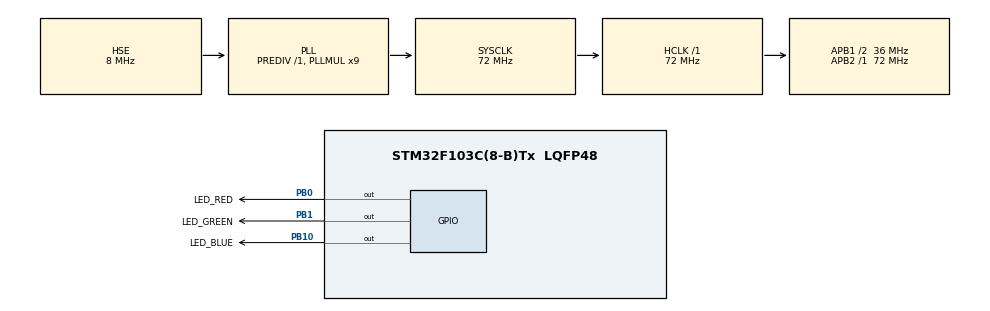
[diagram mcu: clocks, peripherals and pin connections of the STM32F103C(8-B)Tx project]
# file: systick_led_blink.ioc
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Mcu.Family=STM32F1
Mcu.Name=STM32F103C(8-B)Tx
Mcu.Package=LQFP48
NVIC.PriorityGroup=NVIC_PRIORITYGROUP_4
PA13.Mode=Serial_Wire
PA13.Signal=SYS_JTMS-SWDIO
PA14.Mode=Serial_Wire
PA14.Signal=SYS_JTCK-SWCLK
PB0.GPIO_Label=LED_RED
PB0.PinState=GPIO_PIN_SET
PB0.Signal=GPIO_Output
PB1.GPIO_Label=LED_GREEN
PB1.PinState=GPIO_PIN_SET
PB1.Signal=GPIO_Output
PB10.GPIO_Label=LED_BLUE
PB10.PinState=GPIO_PIN_SET
PB10.Signal=GPIO_Output
PD0-OSC_IN.Mode=HSE-External-Oscillator
PD0-OSC_IN.Signal=RCC_OSC_IN
PD1-OSC_OUT.Mode=HSE-External-Oscillator
PD1-OSC_OUT.Signal=RCC_OSC_OUT
ProjectManager.HeapSize=0x200
ProjectManager.StackSize=0x400
ProjectManager.TargetToolchain=CMake
RCC.AHBFreq_Value=72000000
RCC.APB1CLKDivider=RCC_HCLK_DIV2
RCC.APB1Freq_Value=36000000
RCC.APB1TimFreq_Value=72000000
RCC.APB2Freq_Value=72000000
RCC.APB2TimFreq_Value=72000000
RCC.HCLKFreq_Value=72000000
RCC.PLLMUL=RCC_PLL_MUL9
RCC.PLLSourceVirtual=RCC_PLLSOURCE_HSE
RCC.SYSCLKFreq_VALUE=72000000
RCC.SYSCLKSource=RCC_SYSCLKSOURCE_PLLCLK
RCC.USBFreq_Value=72000000
board=custom

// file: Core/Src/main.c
/* USER CODE BEGIN Header */
/**
  ******************************************************************************
  * @file           : main.c
  * @brief          : Main program body
  ******************************************************************************
  * @attention
  *
  * Copyright (c) 2025 STMicroelectronics.
  * All rights reserved.
  *
  * This software is licensed under terms that can be found in the LICENSE file
  * in the root directory of this software component.
  * If no LICENSE file comes with this software, it is provided AS-IS.
  *
  ******************************************************************************
  */
/* USER CODE END Header */
#include "main.h"
#include "gpio.h"
#include "stm32f103xb.h"
#include "stm32f1xx_hal_gpio.h"
#include "stm32f1xx_it.h"
#include <stdint.h>

/* USER CODE BEGIN PD */

// 定义LED引脚和端口
#define LEDR_PIN GPIO_PIN_0
#define LEDR_GPIO_PORT GPIOB
#define LEDG_PIN GPIO_PIN_1
#define LEDG_GPIO_PORT GPIOB
#define LEDB_PIN GPIO_PIN_10
#define LEDB_GPIO_PORT GPIOB

/* USER CODE END PD */

/* USER CODE BEGIN PV */

volatile uint32_t tick_count = 0; // 毫秒计数器
volatile uint8_t led_state = 0;  // LED状态变量, 0: 红, 1: 绿, 2: 蓝

/* USER CODE END PV */

void SystemClock_Config(void);
/* USER CODE BEGIN PFP */

void SysTick_Init(uint32_t ticks);
void SysTick_Handler(void);

/* USER CODE END PFP */

/* USER CODE BEGIN 0 */

/**
  * @brief  初始化SysTick定时器
  * @param  ticks: 定时器重载值
  * @retval None
  */
void SysTick_Init(uint32_t ticks) {
  // 关闭SysTick定时器
  SysTick->CTRL = 0;

  // 设置重载寄存器
  SysTick->LOAD = ticks - 1;

  // 设置中断优先级
  NVIC_SetPriority(SysTick_IRQn, 0x0);

  // 重置计数器
  SysTick->VAL = 0;

  // 启用SysTick定时器，选择系统时钟，并启用中断
  SysTick->CTRL = SysTick_CTRL_CLKSOURCE_Msk |
                 SysTick_CTRL_TICKINT_Msk |
                 SysTick_CTRL_ENABLE_Msk;
}

/**
  * @brief  SysTick中断服务程序
  * @param  None
  * @retval None
  */
void SysTick_Handler(void)
{
  /* USER CODE BEGIN SysTick_IRQn 0 */

  tick_count++;

  // 每1000ms切换一次LED状态
  if (tick_count % 1000 == 0) {
    // 关闭所有LED
    HAL_GPIO_WritePin(LEDR_GPIO_PORT, LEDR_PIN, GPIO_PIN_SET);
    HAL_GPIO_WritePin(LEDG_GPIO_PORT, LEDG_PIN, GPIO_PIN_SET);
    HAL_GPIO_WritePin(LEDB_GPIO_PORT, LEDB_PIN, GPIO_PIN_SET);

   // 根据当前状态点亮对应的LED
    switch (led_state) {
      case 0:
        HAL_GPIO_WritePin(LEDR_GPIO_PORT, LEDR_PIN, GPIO_PIN_RESET); // 点亮红色LED
        break;
      case 1:
        HAL_GPIO_WritePin(LEDG_GPIO_PORT, LEDG_PIN, GPIO_PIN_RESET); // 点亮绿色LED
        break;
      case 2:
        HAL_GPIO_WritePin(LEDB_GPIO_PORT, LEDB_PIN, GPIO_PIN_RESET); // 点亮蓝色LED
        break;
    }

    // 更新LED状态
    led_state = (led_state + 1) % 3; // 循环切换状态
  }

  /* USER CODE END SysTick_IRQn 0 */
  HAL_IncTick();
  /* USER CODE BEGIN SysTick_IRQn 1 */

  /* USER CODE END SysTick_IRQn 1 */
}

/* USER CODE END 0 */

int main(void)
{

  /* MCU Configuration--------------------------------------------------------*/

  /* Reset of all peripherals, Initializes the Flash interface and the Systick. */
  HAL_Init();

  /* Configure the system clock */
  SystemClock_Config();

  /* Initialize all configured peripherals */
  MX_GPIO_Init();
  /* USER CODE BEGIN 2 */

  // 初始化SysTick定时器，系统时钟为72MHz，每1ms中断一次
  SysTick_Init(72000);

  // 初始化时，关闭所有LED
  HAL_GPIO_WritePin(LEDR_GPIO_PORT, LEDR_PIN, GPIO_PIN_SET);
  HAL_GPIO_WritePin(LEDG_GPIO_PORT, LEDG_PIN, GPIO_PIN_SET);
  HAL_GPIO_WritePin(LEDB_GPIO_PORT, LEDB_PIN, GPIO_PIN_SET);

  /* USER CODE END 2 */

  /* Infinite loop */
  while (1)
  {

    /* USER CODE BEGIN 3 */

    // 主循环中不需要做任何事情，所有操作都在SysTick中断中处理
  }
  /* USER CODE END 3 */
}

void SystemClock_Config(void)
{
  RCC_OscInitTypeDef RCC_OscInitStruct = {0};
  RCC_ClkInitTypeDef RCC_ClkInitStruct = {0};

  /** Initializes the RCC Oscillators according to the specified parameters
  * in the RCC_OscInitTypeDef structure.
  */
  RCC_OscInitStruct.OscillatorType = RCC_OSCILLATORTYPE_HSE;
  RCC_OscInitStruct.HSEState = RCC_HSE_ON;
  RCC_OscInitStruct.HSEPredivValue = RCC_HSE_PREDIV_DIV1;
  RCC_OscInitStruct.HSIState = RCC_HSI_ON;
  RCC_OscInitStruct.PLL.PLLState = RCC_PLL_ON;
  RCC_OscInitStruct.PLL.PLLSource = RCC_PLLSOURCE_HSE;
  RCC_OscInitStruct.PLL.PLLMUL = RCC_PLL_MUL9;
  if (HAL_RCC_OscConfig(&RCC_OscInitStruct) != HAL_OK)
  {
    Error_Handler();
  }

  /** Initializes the CPU, AHB and APB buses clocks
  */
  RCC_ClkInitStruct.ClockType = RCC_CLOCKTYPE_HCLK|RCC_CLOCKTYPE_SYSCLK
                              |RCC_CLOCKTYPE_PCLK1|RCC_CLOCKTYPE_PCLK2;
  RCC_ClkInitStruct.SYSCLKSource = RCC_SYSCLKSOURCE_PLLCLK;
  RCC_ClkInitStruct.AHBCLKDivider = RCC_SYSCLK_DIV1;
  RCC_ClkInitStruct.APB1CLKDivider = RCC_HCLK_DIV2;
  RCC_ClkInitStruct.APB2CLKDivider = RCC_HCLK_DIV1;

  if (HAL_RCC_ClockConfig(&RCC_ClkInitStruct, FLASH_LATENCY_2) != HAL_OK)
  {
    Error_Handler();
  }
}

void Error_Handler(void)
{
  /* USER CODE BEGIN Error_Handler_Debug */
  /* User can add his own implementation to report the HAL error return state */
  __disable_irq();
  while (1)
  {
    // 错误时红灯闪烁
    HAL_GPIO_TogglePin(LEDR_GPIO_PORT, LEDR_PIN);
    HAL_Delay(500);
  }
  /* USER CODE END Error_Handler_Debug */
}
